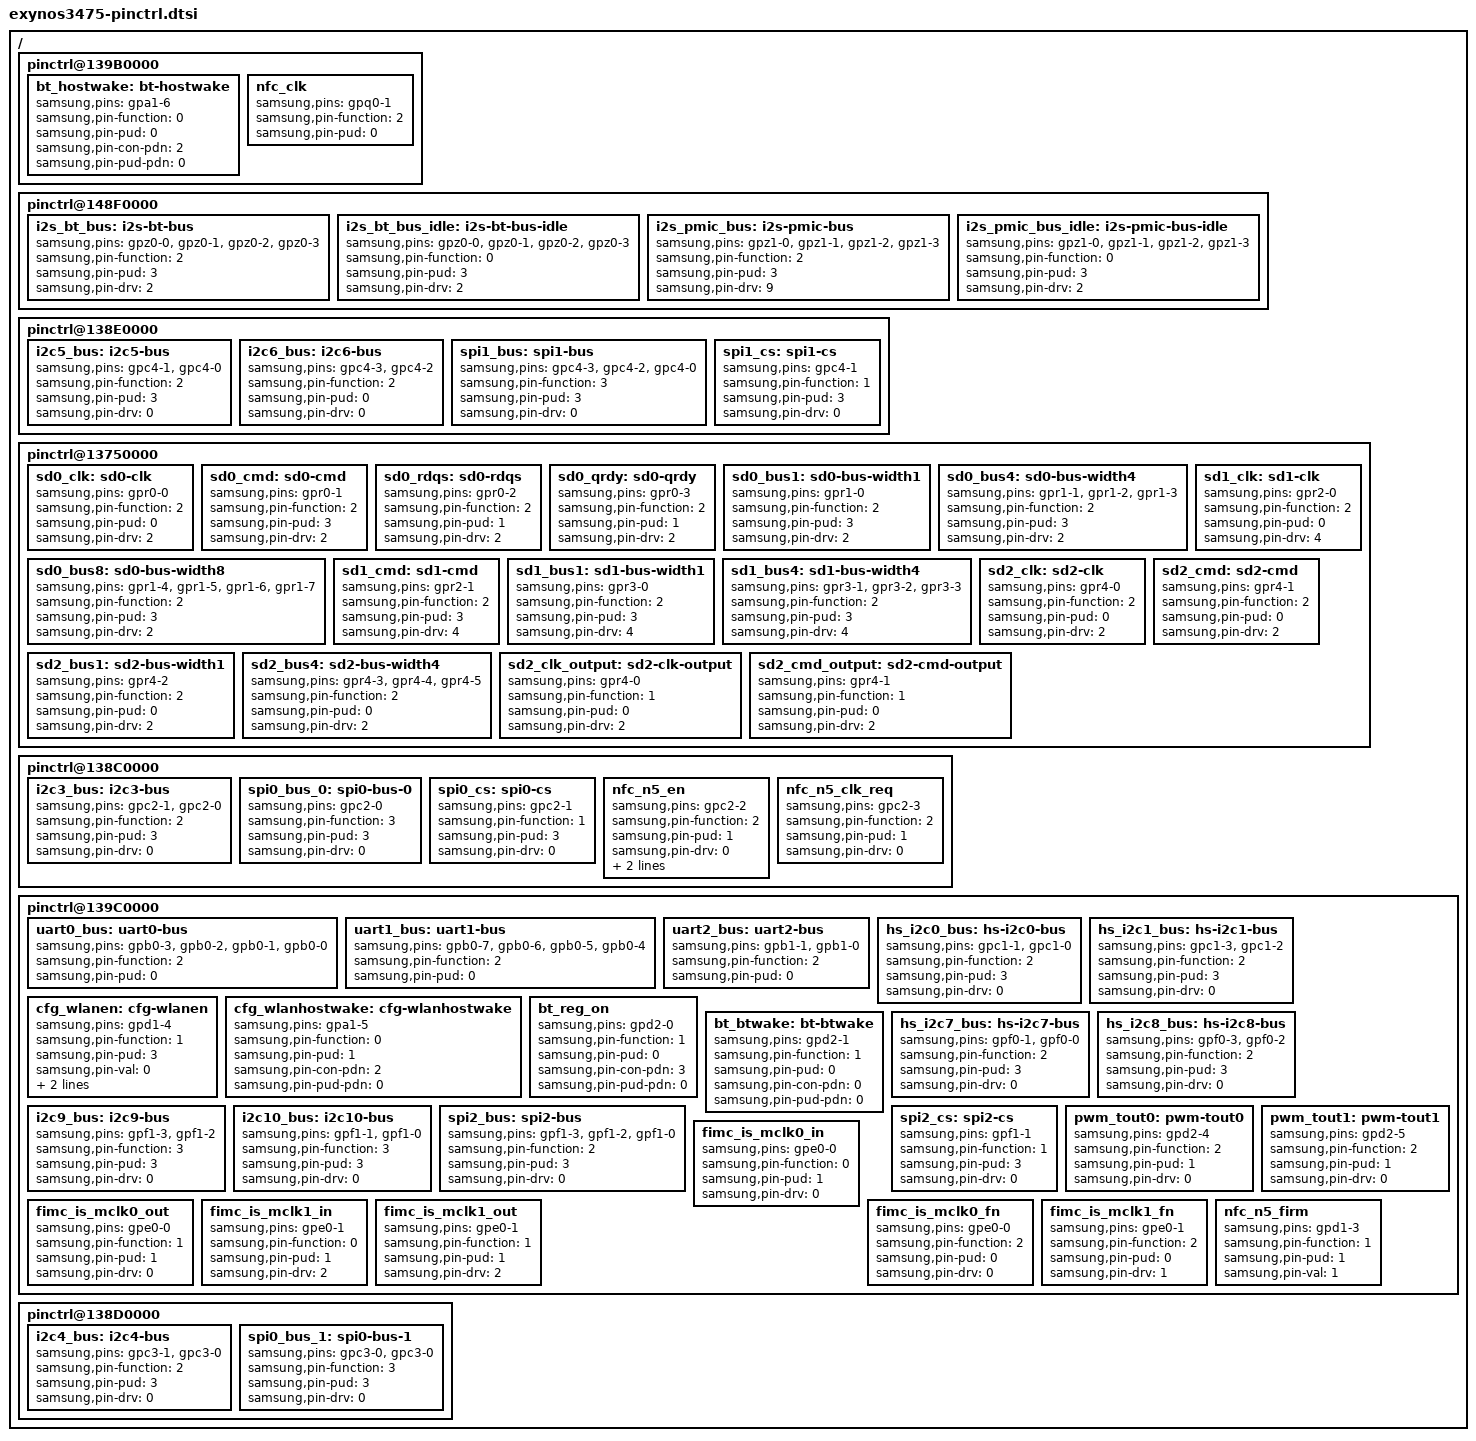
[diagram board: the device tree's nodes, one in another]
/ {
	/* ALIVE */
	pinctrl@139B0000 {
		bt_hostwake: bt-hostwake {
			samsung,pins = "gpa1-6";
			samsung,pin-function = <0>;
			samsung,pin-pud = <0>;
			samsung,pin-con-pdn = <2>;
			samsung,pin-pud-pdn = <0>;
		};
	};

	/* AUD */
    pinctrl@148F0000 {
		i2s_bt_bus: i2s-bt-bus {
			samsung,pins = "gpz0-0", "gpz0-1", "gpz0-2", "gpz0-3";
			samsung,pin-function = <2>;
			samsung,pin-pud = <3>;
			samsung,pin-drv = <2>;
		};

		i2s_bt_bus_idle: i2s-bt-bus-idle {
			samsung,pins = "gpz0-0", "gpz0-1", "gpz0-2", "gpz0-3";
			samsung,pin-function = <0>;
			samsung,pin-pud = <3>;
			samsung,pin-drv = <2>;
		};

		i2s_pmic_bus: i2s-pmic-bus {
			samsung,pins = "gpz1-0", "gpz1-1", "gpz1-2", "gpz1-3";
			samsung,pin-function = <2>;
			samsung,pin-pud = <3>;
			samsung,pin-drv = <9>;
		};

		i2s_pmic_bus_idle: i2s-pmic-bus-idle {
			samsung,pins = "gpz1-0", "gpz1-1", "gpz1-2", "gpz1-3";
			samsung,pin-function = <0>;
			samsung,pin-pud = <3>;
			samsung,pin-drv = <2>;
		};
	};

	/* ESE */
	pinctrl@138E0000 {
		i2c5_bus: i2c5-bus {
			samsung,pins = "gpc4-1", "gpc4-0";
			samsung,pin-function = <2>;
			samsung,pin-pud = <3>;
			samsung,pin-drv = <0>;
		};

		i2c6_bus: i2c6-bus {
			samsung,pins = "gpc4-3", "gpc4-2";
			samsung,pin-function = <2>;
			samsung,pin-pud = <0>;
			samsung,pin-drv = <0>;
		};

		spi1_bus: spi1-bus {
			samsung,pins = "gpc4-3", "gpc4-2", "gpc4-0";
			samsung,pin-function = <3>;
			samsung,pin-pud = <3>;
			samsung,pin-drv = <0>;
		};

		spi1_cs: spi1-cs {
			samsung,pins = "gpc4-1";
			samsung,pin-function = <1>;
			samsung,pin-pud = <3>;
			samsung,pin-drv = <0>;
		};

	};


	/* FSYS */
	pinctrl@13750000 {
		sd0_clk: sd0-clk {
			samsung,pins = "gpr0-0";
			samsung,pin-function = <2>;
			samsung,pin-pud = <0>;
			samsung,pin-drv = <2>;
		};

		sd0_cmd: sd0-cmd {
			samsung,pins = "gpr0-1";
			samsung,pin-function = <2>;
			samsung,pin-pud = <3>;
			samsung,pin-drv = <2>;
		};

		sd0_rdqs: sd0-rdqs {
			samsung,pins = "gpr0-2";
			samsung,pin-function = <2>;
			samsung,pin-pud = <1>;
			samsung,pin-drv = <2>;
		};

		sd0_qrdy: sd0-qrdy {
			samsung,pins = "gpr0-3";
			samsung,pin-function = <2>;
			samsung,pin-pud = <1>;
			samsung,pin-drv = <2>;
		};

		sd0_bus1: sd0-bus-width1 {
			samsung,pins = "gpr1-0";
			samsung,pin-function = <2>;
			samsung,pin-pud = <3>;
			samsung,pin-drv = <2>;
		};

		sd0_bus4: sd0-bus-width4 {
			samsung,pins = "gpr1-1", "gpr1-2", "gpr1-3";
			samsung,pin-function = <2>;
			samsung,pin-pud = <3>;
			samsung,pin-drv = <2>;
		};

		sd0_bus8: sd0-bus-width8 {
			samsung,pins = "gpr1-4", "gpr1-5", "gpr1-6", "gpr1-7";
			samsung,pin-function = <2>;
			samsung,pin-pud = <3>;
			samsung,pin-drv = <2>;
		};

		sd1_clk: sd1-clk {
			samsung,pins = "gpr2-0";
			samsung,pin-function = <2>;
			samsung,pin-pud = <0>;
			samsung,pin-drv = <4>;
		};

		sd1_cmd: sd1-cmd {
			samsung,pins = "gpr2-1";
			samsung,pin-function = <2>;
			samsung,pin-pud = <3>;
			samsung,pin-drv = <4>;
		};

		sd1_bus1: sd1-bus-width1 {
			samsung,pins = "gpr3-0";
			samsung,pin-function = <2>;
			samsung,pin-pud = <3>;
			samsung,pin-drv = <4>;
		};

		sd1_bus4: sd1-bus-width4 {
			samsung,pins = "gpr3-1", "gpr3-2", "gpr3-3";
			samsung,pin-function = <2>;
			samsung,pin-pud = <3>;
			samsung,pin-drv = <4>;
		};

		sd2_clk: sd2-clk {
			samsung,pins = "gpr4-0";
			samsung,pin-function = <2>;
			samsung,pin-pud = <0>;
			samsung,pin-drv = <2>;
		};

		sd2_cmd: sd2-cmd {
			samsung,pins = "gpr4-1";
			samsung,pin-function = <2>;
			samsung,pin-pud = <0>;
			samsung,pin-drv = <2>;
		};

		sd2_bus1: sd2-bus-width1 {
			samsung,pins = "gpr4-2";
			samsung,pin-function = <2>;
			samsung,pin-pud = <0>;
			samsung,pin-drv = <2>;
		};

		sd2_bus4: sd2-bus-width4 {
			samsung,pins = "gpr4-3", "gpr4-4", "gpr4-5";
			samsung,pin-function = <2>;
			samsung,pin-pud = <0>;
			samsung,pin-drv = <2>;
		};

		/* Set output */
		sd2_clk_output: sd2-clk-output {
			samsung,pins = "gpr4-0";
			samsung,pin-function = <1>;
			samsung,pin-pud = <0>;
			samsung,pin-drv = <2>;
		};

		sd2_cmd_output: sd2-cmd-output {
			samsung,pins = "gpr4-1";
			samsung,pin-function = <1>;
			samsung,pin-pud = <0>;
			samsung,pin-drv = <2>;
		};
	};

    /* MIF */
    pinctrl@138C0000 {
		i2c3_bus: i2c3-bus {
			samsung,pins = "gpc2-1", "gpc2-0";
			samsung,pin-function = <2>;
			samsung,pin-pud = <3>;
			samsung,pin-drv = <0>;
		};

		spi0_bus_0: spi0-bus-0 {
			samsung,pins = "gpc2-0";
			samsung,pin-function = <3>;
			samsung,pin-pud = <3>;
			samsung,pin-drv = <0>;
		};

		spi0_cs: spi0-cs {
			samsung,pins = "gpc2-1";
			samsung,pin-function = <1>;
			samsung,pin-pud = <3>;
			samsung,pin-drv = <0>;
		};

		nfc_n5_en: nfc_n5_en {
			samsung,pins = "gpc2-2";
			samsung,pin-function = <2>;
			samsung,pin-pud = <1>;
			samsung,pin-drv = <0>;
			samsung,pin-con-pdn = <3>;
			samsung,pin-pud-pdn = <0>;
		};

		nfc_n5_clk_req: nfc_n5_clk_req {
			samsung,pins = "gpc2-3";
			samsung,pin-function = <2>;
			samsung,pin-pud = <1>;
			samsung,pin-drv = <0>;
		};
	};

    /* NFC */
    pinctrl@139B0000 {
		nfc_clk: nfc_clk {
			samsung,pins = "gpq0-1";
			samsung,pin-function = <2>;
			samsung,pin-pud = <0>;
		};
	};

    /* TOP */
    pinctrl@139C0000 {
		uart0_bus: uart0-bus {
			samsung,pins = "gpb0-3", "gpb0-2", "gpb0-1", "gpb0-0";
			samsung,pin-function = <2>;
			samsung,pin-pud = <0>;
		};

		uart1_bus: uart1-bus {
			samsung,pins = "gpb0-7", "gpb0-6", "gpb0-5", "gpb0-4";
			samsung,pin-function = <2>;
			samsung,pin-pud = <0>;
		};

		uart2_bus: uart2-bus {
			samsung,pins = "gpb1-1", "gpb1-0";
			samsung,pin-function = <2>;
			samsung,pin-pud = <0>;
		};

		hs_i2c0_bus: hs-i2c0-bus {
			samsung,pins = "gpc1-1", "gpc1-0";
			samsung,pin-function = <2>;
			samsung,pin-pud = <3>;
			samsung,pin-drv = <0>;
		};

		hs_i2c1_bus: hs-i2c1-bus {
			samsung,pins = "gpc1-3", "gpc1-2";
			samsung,pin-function = <2>;
			samsung,pin-pud = <3>;
			samsung,pin-drv = <0>;
		};

		cfg_wlanen: cfg-wlanen {
			samsung,pins = "gpd1-4";
			samsung,pin-function = <1>;
			samsung,pin-pud = <3>;
			samsung,pin-val = <0>;
			samsung,pin-drv = <0>;
			samsung,pin-con-pdn = <3>;
		};

		cfg_wlanhostwake: cfg-wlanhostwake {
			samsung,pins = "gpa1-5";
			samsung,pin-function = <0>;
			samsung,pin-pud = <1>;
			samsung,pin-con-pdn = <2>;
			samsung,pin-pud-pdn = <0>;
		};

		bt_reg_on: bt_reg_on {
			samsung,pins ="gpd2-0";
			samsung,pin-function = <1>;
			samsung,pin-pud = <0>;
			samsung,pin-con-pdn = <3>;
			samsung,pin-pud-pdn = <0>;
		};

		bt_btwake: bt-btwake {
			samsung,pins = "gpd2-1";
			samsung,pin-function = <1>;
			samsung,pin-pud = <0>;
			samsung,pin-con-pdn = <0>;
			samsung,pin-pud-pdn = <0>;
		};

		hs_i2c7_bus: hs-i2c7-bus {
			samsung,pins = "gpf0-1", "gpf0-0";
			samsung,pin-function = <2>;
			samsung,pin-pud = <3>;
			samsung,pin-drv = <0>;
		};

		hs_i2c8_bus: hs-i2c8-bus {
			samsung,pins = "gpf0-3", "gpf0-2";
			samsung,pin-function = <2>;
			samsung,pin-pud = <3>;
			samsung,pin-drv = <0>;
		};

		i2c9_bus: i2c9-bus {
			samsung,pins = "gpf1-3", "gpf1-2";
			samsung,pin-function = <3>;
			samsung,pin-pud = <3>;
			samsung,pin-drv = <0>;
		};

		i2c10_bus: i2c10-bus {
			samsung,pins = "gpf1-1", "gpf1-0";
			samsung,pin-function = <3>;
			samsung,pin-pud = <3>;
			samsung,pin-drv = <0>;
		};

		spi2_bus: spi2-bus {
			samsung,pins = "gpf1-3", "gpf1-2", "gpf1-0";
			samsung,pin-function = <2>;
			samsung,pin-pud = <3>;
			samsung,pin-drv = <0>;
		};

		spi2_cs: spi2-cs {
			samsung,pins = "gpf1-1";
			samsung,pin-function = <1>;
			samsung,pin-pud = <3>;
			samsung,pin-drv = <0>;
		};

		pwm_tout0: pwm-tout0 {
			samsung,pins = "gpd2-4";
			samsung,pin-function = <2>;
			samsung,pin-pud = <1>;
			samsung,pin-drv = <0>;
		};

		pwm_tout1: pwm-tout1 {
			samsung,pins = "gpd2-5";
			samsung,pin-function = <2>;
			samsung,pin-pud = <1>;
			samsung,pin-drv = <0>;
		};

		fimc_is_mclk0_in: fimc_is_mclk0_in {
			samsung,pins = "gpe0-0";
			samsung,pin-function = <0>;
			samsung,pin-pud = <1>;
			samsung,pin-drv = <0>;
		};

		fimc_is_mclk0_out: fimc_is_mclk0_out {
			samsung,pins = "gpe0-0";
			samsung,pin-function = <1>;
			samsung,pin-pud = <1>;
			samsung,pin-drv = <0>;
		};

		fimc_is_mclk1_in: fimc_is_mclk1_in {
			samsung,pins = "gpe0-1";
			samsung,pin-function = <0>;
			samsung,pin-pud = <1>;
			samsung,pin-drv = <2>;
		};

		fimc_is_mclk1_out: fimc_is_mclk1_out {
			samsung,pins = "gpe0-1";
			samsung,pin-function = <1>;
			samsung,pin-pud = <1>;
			samsung,pin-drv = <2>;
		};

		fimc_is_mclk0_fn: fimc_is_mclk0_fn {
			samsung,pins = "gpe0-0";
			samsung,pin-function = <2>;
			samsung,pin-pud = <0>;
			samsung,pin-drv = <0>;
		};

		fimc_is_mclk1_fn: fimc_is_mclk1_fn {
			samsung,pins = "gpe0-1";
			samsung,pin-function = <2>;
			samsung,pin-pud = <0>;
			samsung,pin-drv = <1>;
		};

		nfc_n5_firm: nfc_n5_firm {
			samsung,pins = "gpd1-3";
			samsung,pin-function = <1>;
			samsung,pin-pud = <1>;
			samsung,pin-val = <1>;
		};
	};

    /* TOUCH */
    pinctrl@138D0000 {
		i2c4_bus: i2c4-bus {
			samsung,pins = "gpc3-1", "gpc3-0";
			samsung,pin-function = <2>;
			samsung,pin-pud = <3>;
			samsung,pin-drv = <0>;
		};

		spi0_bus_1: spi0-bus-1 {
			samsung,pins = "gpc3-0", "gpc3-0";
			samsung,pin-function = <3>;
			samsung,pin-pud = <3>;
			samsung,pin-drv = <0>;
		};
	};
};
